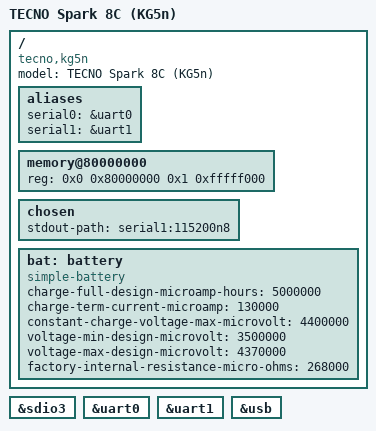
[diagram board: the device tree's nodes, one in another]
// SPDX-License-Identifier: (GPL-2.0 OR MIT)
/*
 * TECNO Spark 8C (KG5n) - Unisoc UMS9230 (Tiger T606) - U-Boot board
 *
 * Minimal headless board: UART console, eMMC (sdio3, rootfs), USB.
 * Derived from ums9230-reeder-s19mps.dts (same UMS9230 reference family);
 * the reeder uses UFS as internal storage, KG5n uses eMMC.
 */

/dts-v1/;

#include "ums9230.dtsi"
#include "sc2730.dtsi"

/ {
	model = "TECNO Spark 8C (KG5n)";
	compatible = "tecno,kg5n", "sprd,ums9230";

	aliases {
		serial0 = &uart0;
		serial1 = &uart1;
	};

	memory@80000000 {
		device_type = "memory";
		reg = <0x0 0x80000000 0x1 0xfffff000>;
	};

	chosen {
		#address-cells = <2>;
		#size-cells = <2>;
		ranges;
		stdout-path = "serial1:115200n8";
	};

	bat: battery {
		compatible = "simple-battery";
		charge-full-design-microamp-hours = <5000000>;
		charge-term-current-microamp = <130000>;
		constant-charge-voltage-max-microvolt = <4400000>;
		voltage-min-design-microvolt = <3500000>;
		voltage-max-design-microvolt = <4370000>;
		factory-internal-resistance-micro-ohms = <268000>;
	};
};

/* eMMC (internal storage / rootfs) */
&sdio3 {
	status = "okay";
};

&uart0 {
	status = "okay";
};

&uart1 {
	status = "okay";
};

&usb {
	status = "okay";
};
